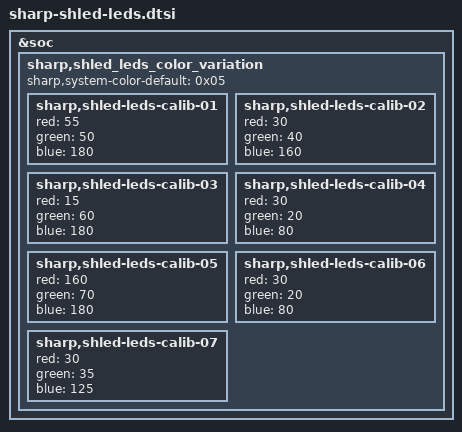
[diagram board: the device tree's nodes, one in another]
/* Copyright (c) 2018, The Linux Foundation. All rights reserved.
 *
 * This program is free software; you can redistribute it and/or modify
 * it under the terms of the GNU General Public License version 2 and
 * only version 2 as published by the Free Software Foundation.
 *
 * This program is distributed in the hope that it will be useful,
 * but WITHOUT ANY WARRANTY; without even the implied warranty of
 * MERCHANTABILITY or FITNESS FOR A PARTICULAR PURPOSE.  See the
 * GNU General Public License for more details.
 */

&soc {
	/*-------------------------------*/
	/* LED color variation parameter */
	/*-------------------------------*/
	sharp,shled_leds_color_variation {
		sharp,system-color-default = <0x05>;

		sharp,shled-leds-calib-01 {
			red = <55>;
			green = <50>;
			blue = <180>;
		};

		sharp,shled-leds-calib-02 {
			red = <30>;
			green = <40>;
			blue = <160>;
		};

		sharp,shled-leds-calib-03 {
			red = <15>;
			green = <60>;
			blue = <180>;
		};

		sharp,shled-leds-calib-04 {
			red = <30>;
			green = <20>;
			blue = <80>;
		};

		sharp,shled-leds-calib-05 {
			red = <160>;
			green = <70>;
			blue = <180>;
		};

		sharp,shled-leds-calib-06 {
			red = <30>;
			green = <20>;
			blue = <80>;
		};

		sharp,shled-leds-calib-07 {
			red = <30>;
			green = <35>;
			blue = <125>;
		};
	};
};
